# PY32F071Cxx register map
Vendor: Puya; Series: PY32F0; File version: 1.0.0
CPU: CM0+ r0p1, little endian, no MPU, no FPU, 4 interrupt priority bits
Registers are 32-bit, read-write, reset 0x0 unless marked. A register's access mark holds for its fields unless they carry their own. Offsets are from the block's base; [hi:lo] are bit positions; {n}, {i} and the like mark numbered series.

## IWDG — Independent watchdog
Base 0x40003000
0x00 KR wo — Key register (IWDG_KR)
  [15:0] KEY — Key value
0x04 PR — Prescaler register (IWDG_PR)
  [2:0] PR — Prescaler divider
    1=0; 2=1; 4=2
0x08 RLR reset 0xFFF — Reload register (IWDG_RLR)
  [11:0] RL — Watchdog counter reload value
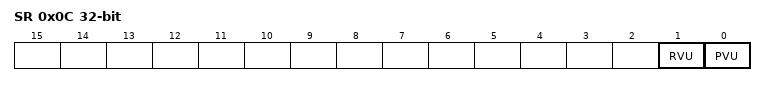
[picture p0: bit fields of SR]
0x0C SR ro — Status register (IWDG_SR)
  [1] RVU — Watchdog counter reload value update
  [0] PVU — Watchdog prescaler value update

## LCD — LCD CONTROLLER
Base 0x40002400
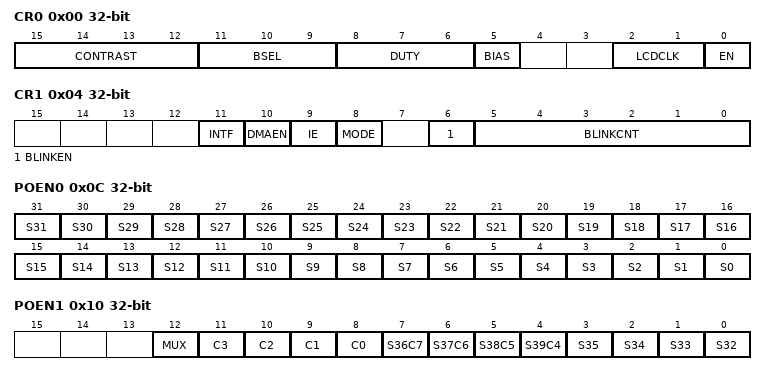
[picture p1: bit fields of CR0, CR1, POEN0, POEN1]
0x00 CR0 — Control register
  [15:12] CONTRAST
    1=0; 2=1; 4=2; 8=3
  [11:9] BSEL
    1=0; 2=1; 4=2
  [8:6] DUTY
    1=0; 2=1; 4=2
  [5] BIAS
  [2:1] LCDCLK
    1=0; 2=1
  [0] EN
0x04 CR1
  [11] INTF
  [10] DMAEN
  [9] IE
  [8] MODE
  [6] BLINKEN
  [5:0] BLINKCNT
    1=0; 2=1; 4=2; 8=3; 16=4; 32=5
0x08 INTCLR
  [10] INTF_CLR
0x0C POEN0
  [n] S{n} (n=0..31)
0x10 POEN1
  [12] MUX
  [n+8] C{n} (n=0..3)
  [7] S36C7 — S36
  [6] S37C6 — S37
  [5] S38C5 — S38
  [4] S39C4 — S39
  [n-32] S{n} (n=32..35)
{0x14+4i} RAM{i} (i=0..7) — des RAM{i}
  [31:0] D — des D
{0x14+4i} RAM{i} (i=8..15) — des RAM{i}
  [7:0] D — des D

## LPTIM1 — Low power timer
Base 0x40007C00
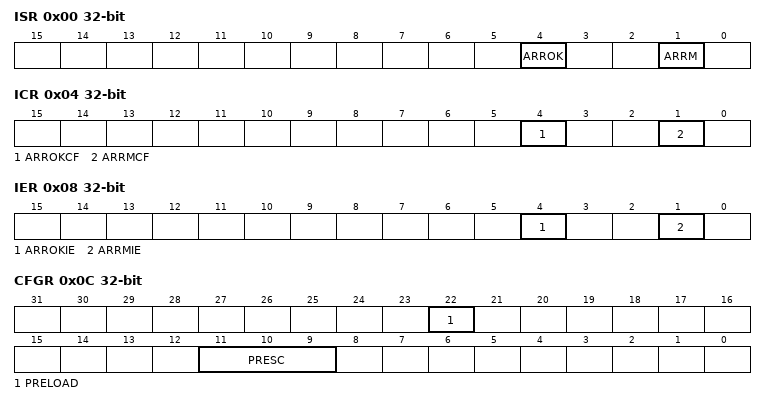
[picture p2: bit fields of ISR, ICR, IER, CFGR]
0x00 ISR ro — Interrupt and Status Register
  [4] ARROK — Autoreload match update OK
  [1] ARRM — Autoreload match
0x04 ICR wo — Interrupt Clear Register
  [4] ARROKCF — Autoreload match update OK Clear Flag
  [1] ARRMCF — Autoreload match Clear Flag
0x08 IER — Interrupt Enable Register
  [4] ARROKIE — Autoreload match update OK Interrupt Enable
  [1] ARRMIE — Autoreload matchInterrupt Enable
0x0C CFGR — Configuration Register
  [22] PRELOAD — Registers update mode
  [11:9] PRESC — Clock prescaler
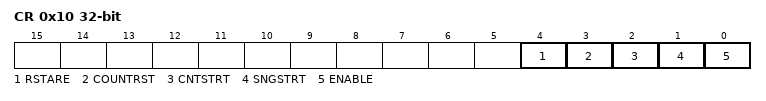
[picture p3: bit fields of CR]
0x10 CR — Control Register
  [4] RSTARE — Reset after read enable
  [3] COUNTRST — LPTIM counter reset
  [2] CNTSTRT
  [1] SNGSTRT — LPTIM start in single mode
  [0] ENABLE — LPTIM Enable
0x18 ARR reset 0x1 — Autoreload Register
  [15:0] ARR — Auto reload value
0x1C CNT ro — Counter Register
  [15:0] CNT — Counter value

## OPA — des OPA
Base 0x40010300
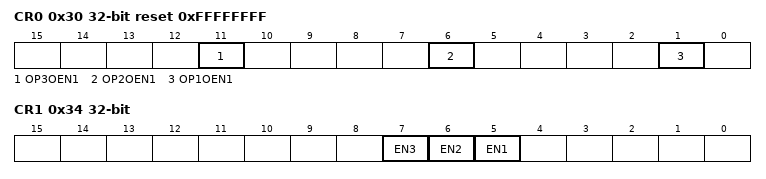
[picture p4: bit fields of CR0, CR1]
0x30 CR0 reset 0xFFFFFFFF
  [11] OP3OEN1, [6] OP2OEN1, [1] OP1OEN1
0x34 CR1
  [7] EN3, [6] EN2, [5] EN1

## PWR — Power control
Base 0x40007000
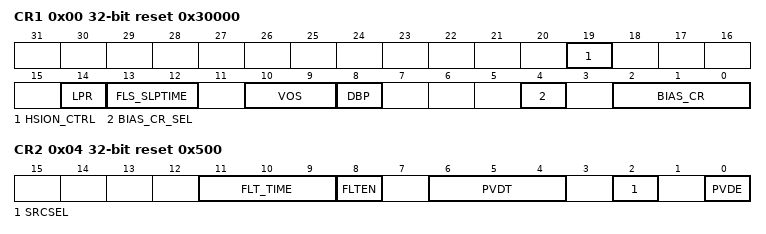
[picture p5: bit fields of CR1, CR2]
0x00 CR1 reset 0x30000 — Power control register 1
  [19] HSION_CTRL — HSI open time control
  [14] LPR — Low-power run
  [13:12] FLS_SLPTIME — Flash wait time after wakeup from the stop mode
    1=0; 2=1
  [10:9] VOS — Voltage scaling range selection
    1=0; 2=1
  [8] DBP — Disable backup domain write protection
  [4] BIAS_CR_SEL — MR Bias current selection
  [2:0] BIAS_CR — MR Bias current
0x04 CR2 reset 0x500 — Power control register 2
  [11:9] FLT_TIME — Digital filter time configuration
    1=0; 2=1; 4=2
  [8] FLTEN — Digital filter enable
  [6:4] PVDT — Power voltage detector threshold selection
    1=0; 2=1; 4=2
  [2] SRCSEL — Power voltage detector volatage selection
  [0] PVDE — Power voltage detector enable
0x14 SR ro — Power status register
  [11] PVDO — PVD output

## RTC
Base 0x40002800
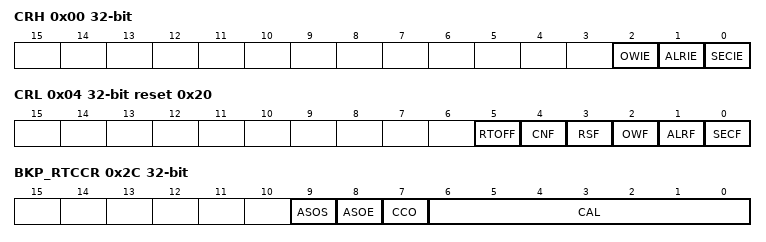
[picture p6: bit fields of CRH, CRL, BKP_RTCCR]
0x00 CRH
  [2] OWIE, [1] ALRIE, [0] SECIE
0x04 CRL reset 0x20
  [5] RTOFF ro, [4] CNF, [3] RSF, [2] OWF, [1] ALRF, [0] SECF
0x08 PRLH wo
  [3:0] PRL
0x0C PRLL wo reset 0x8000
  [15:0] PRL
0x10 DIVH ro
  [3:0] DIV
0x14 DIVL ro reset 0x8000
  [15:0] DIV
0x18 CNTH
  [15:0] RTC_CNT
0x1C CNTL
  [15:0] RTC_CNT
0x20 ALRH reset 0xFFFF
  [15:0] RTC_ALR
0x24 ALRL reset 0xFFFF
  [15:0] RTC_ALR
0x2C BKP_RTCCR
  [9] ASOS, [8] ASOE, [7] CCO, [6:0] CAL

## SPI1 — Serial peripheral interface
Base 0x40013000
Same registers: SPI2 0x40003800
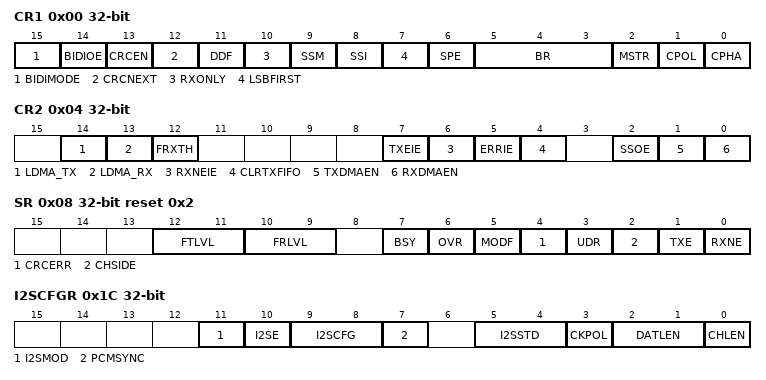
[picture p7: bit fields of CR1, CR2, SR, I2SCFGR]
0x00 CR1
  [15] BIDIMODE
  [14] BIDIOE
  [13] CRCEN
  [12] CRCNEXT
  [11] DDF
  [10] RXONLY
  [9] SSM
  [8] SSI
  [7] LSBFIRST
  [6] SPE
  [5:3] BR
    1=0; 2=1; 4=2
  [2] MSTR
  [1] CPOL
  [0] CPHA
0x04 CR2
  [14] LDMA_TX, [13] LDMA_RX, [12] FRXTH, [7] TXEIE, [6] RXNEIE, [5] ERRIE, [4] CLRTXFIFO, [2] SSOE, [1] TXDMAEN, [0] RXDMAEN
0x08 SR reset 0x2
  [12:11] FTLVL ro
    1=0; 2=1
  [10:9] FRLVL ro
    1=0; 2=1
  [7] BSY ro
  [6] OVR ro
  [5] MODF ro
  [4] CRCERR
  [3] UDR ro
  [2] CHSIDE ro
  [1] TXE ro
  [0] RXNE ro
0x0C DR
  [15:0] DR
0x10 CRCPR reset 0x7
  [15:0] CRCPOLY
0x14 RXCRCR ro
  [15:0] RXCRC
0x18 TXCRCR ro
  [15:0] TXCRC
0x1C I2SCFGR
  [11] I2SMOD
  [10] I2SE
  [9:8] I2SCFG
    1=0; 2=1
  [7] PCMSYNC
  [5:4] I2SSTD
    1=0; 2=1
  [3] CKPOL
  [2:1] DATLEN
    1=0; 2=1
  [0] CHLEN
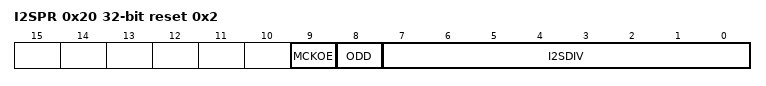
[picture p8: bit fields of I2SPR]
0x20 I2SPR reset 0x2
  [9] MCKOE, [8] ODD, [7:0] I2SDIV
